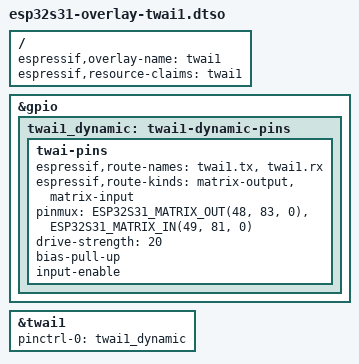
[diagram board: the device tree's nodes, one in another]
// SPDX-License-Identifier: GPL-2.0+
/dts-v1/;
/plugin/;

#include <dt-bindings/pinctrl/esp32s31-pinmux.h>

/ {
	espressif,overlay-name = "twai1";
	espressif,resource-claims = "twai1";
};

&gpio {
	twai1_dynamic: twai1-dynamic-pins {
		twai-pins {
			espressif,route-names = "twai1.tx", "twai1.rx";
			espressif,route-kinds = "matrix-output", "matrix-input";
			pinmux = <ESP32S31_MATRIX_OUT(48, 83, 0)>,
				 <ESP32S31_MATRIX_IN(49, 81, 0)>;
			drive-strength = <20>;
			bias-pull-up;
			input-enable;
		};
	};
};

&twai1 {
	pinctrl-0 = <&twai1_dynamic>;
	status = "okay";
};
